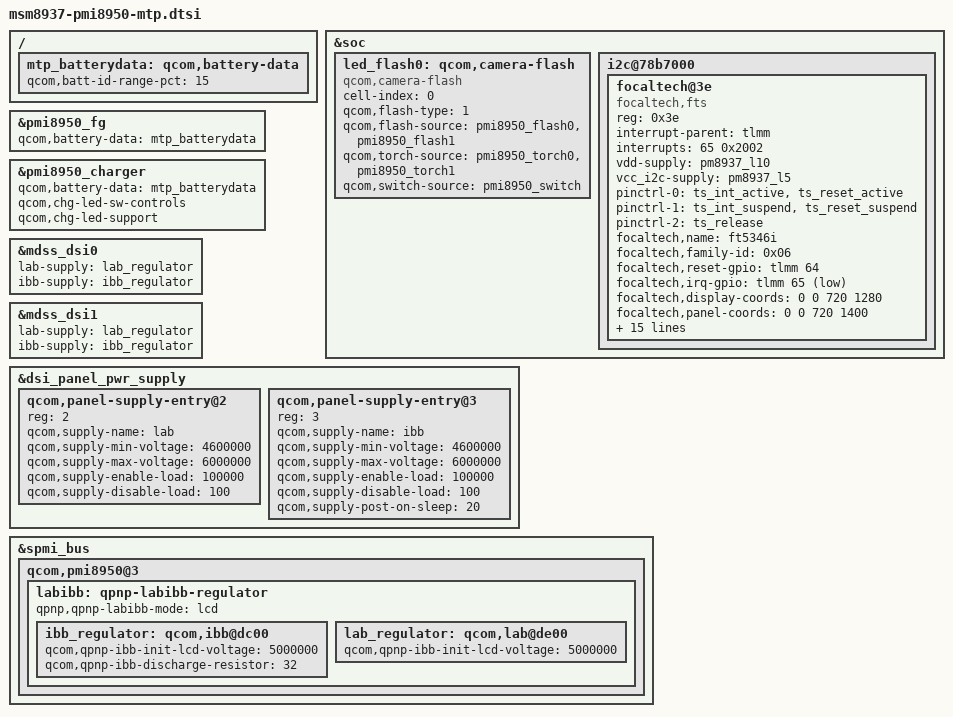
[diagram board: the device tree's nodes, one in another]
/*
 * Copyright (c) 2015-2016, The Linux Foundation. All rights reserved.
 *
 * This program is free software; you can redistribute it and/or modify
 * it under the terms of the GNU General Public License version 2 and
 * only version 2 as published by the Free Software Foundation.
 *
 * This program is distributed in the hope that it will be useful,
 * but WITHOUT ANY WARRANTY; without even the implied warranty of
 * MERCHANTABILITY or FITNESS FOR A PARTICULAR PURPOSE.  See the
 * GNU General Public License for more details.
 */

#include "msm-pmi8950.dtsi"
#include "msm8937-mtp.dtsi"
#include "msm8937-audio-mtp.dtsi"

&soc {
	led_flash0: qcom,camera-flash {
		cell-index = <0>;
		compatible = "qcom,camera-flash";
		qcom,flash-type = <1>;
		qcom,flash-source = <&pmi8950_flash0 &pmi8950_flash1>;
		qcom,torch-source = <&pmi8950_torch0 &pmi8950_torch1>;
		qcom,switch-source = <&pmi8950_switch>;
	};

	i2c@78b7000 {
		status = "ok";
		focaltech@3e {
			compatible = "focaltech,fts";
			reg = <0x3e>;
			interrupt-parent = <&tlmm>;
			interrupts = <65 0x2002>;
			vdd-supply = <&pm8937_l10>;
			vcc_i2c-supply = <&pm8937_l5>;
			/* pins used by touchscreen */
			pinctrl-names = "pmx_ts_active",
					"pmx_ts_suspend",
					"pmx_ts_release";
			pinctrl-0 = <&ts_int_active &ts_reset_active>;
			pinctrl-1 = <&ts_int_suspend &ts_reset_suspend>;
			pinctrl-2 = <&ts_release>;
			focaltech,name = "ft5346i";
			focaltech,family-id = <0x06>;
			focaltech,reset-gpio = <&tlmm 64 0x0>;
			focaltech,irq-gpio = <&tlmm 65 0x1>;
			focaltech,display-coords = <0 0 720 1280>;
			focaltech,panel-coords = <0 0 720 1400>;
			focaltech,button-map= <139 102 158>;
			focaltech,no-force-update;
			focaltech,i2c-pull-up;
			focaltech,group-id = <1>;
			focaltech,hard-reset-delay-ms = <20>;
			focaltech,soft-reset-delay-ms = <200>;
			focaltech,num-max-touches = <5>;
			focaltech,fw-delay-aa-ms = <30>;
			focaltech,fw-delay-55-ms = <30>;
			focaltech,fw-upgrade-id1 = <0x79>;
			focaltech,fw-upgrade-id2 = <0x08>;
			focaltech,fw-delay-readid-ms = <10>;
			focaltech,fw-delay-era-flsh-ms = <2000>;
			focaltech,fw-auto-cal;
			focaltech,ignore-id-check;
		};
	};
};

/{
	mtp_batterydata: qcom,battery-data {
		qcom,batt-id-range-pct = <15>;
		#include "batterydata-itech-3000mah.dtsi"
		#include "batterydata-ascent-3450mAh.dtsi"
	};
};

&pmi8950_fg {
	qcom,battery-data = <&mtp_batterydata>;
};

&pmi8950_charger {
	qcom,battery-data = <&mtp_batterydata>;
	qcom,chg-led-sw-controls;
	qcom,chg-led-support;
};

&mdss_dsi0 {
	lab-supply = <&lab_regulator>;
	ibb-supply = <&ibb_regulator>;
};

&mdss_dsi1 {
	lab-supply = <&lab_regulator>;
	ibb-supply = <&ibb_regulator>;
};

&labibb {
	status = "ok";
	qpnp,qpnp-labibb-mode = "lcd";
};

&ibb_regulator {
	qcom,qpnp-ibb-discharge-resistor = <32>;
};

&dsi_panel_pwr_supply {
	qcom,panel-supply-entry@2 {
		reg = <2>;
		qcom,supply-name = "lab";
		qcom,supply-min-voltage = <4600000>;
		qcom,supply-max-voltage = <6000000>;
		qcom,supply-enable-load = <100000>;
		qcom,supply-disable-load = <100>;
	};

	qcom,panel-supply-entry@3 {
		reg = <3>;
		qcom,supply-name = "ibb";
		qcom,supply-min-voltage = <4600000>;
		qcom,supply-max-voltage = <6000000>;
		qcom,supply-enable-load = <100000>;
		qcom,supply-disable-load = <100>;
		qcom,supply-post-on-sleep = <20>;
	};
};

&spmi_bus {
	qcom,pmi8950@3 {
		labibb: qpnp-labibb-regulator {
			ibb_regulator: qcom,ibb@dc00 {
				/delete-property/
					qcom,qpnp-ibb-use-default-voltage;
				qcom,qpnp-ibb-init-lcd-voltage = <5000000>;
			};

			lab_regulator: qcom,lab@de00 {
				/delete-property/
					qcom,qpnp-ibb-use-default-voltage;
				qcom,qpnp-ibb-init-lcd-voltage = <5000000>;
			};
		};
	};
};

